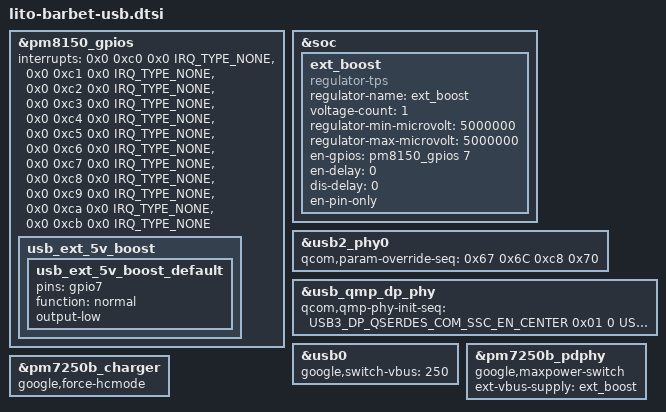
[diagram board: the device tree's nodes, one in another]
// SPDX-License-Identifier: GPL-2.0
/* Copyright (c) 2019, The Linux Foundation. All rights reserved.
 *
 * This program is free software; you can redistribute it and/or modify
 * it under the terms of the GNU General Public License version 2 and
 * only version 2 as published by the Free Software Foundation.
 *
 * This program is distributed in the hope that it will be useful,
 * but WITHOUT ANY WARRANTY; without even the implied warranty of
 * MERCHANTABILITY or FITNESS FOR A PARTICULAR PURPOSE.  See the
 * GNU General Public License for more details.
 */
#include <dt-bindings/phy/qcom,lito-qmp-usb3.h>
#include <dt-bindings/pinctrl/qcom,pmic-gpio.h>

&pm8150_gpios {
	/delete-property/ qcom,gpios-disallowed;
	interrupts = <0x0 0xc0 0x0 IRQ_TYPE_NONE>,
			<0x0 0xc1 0x0 IRQ_TYPE_NONE>,
			<0x0 0xc2 0x0 IRQ_TYPE_NONE>,
			<0x0 0xc3 0x0 IRQ_TYPE_NONE>,
			<0x0 0xc4 0x0 IRQ_TYPE_NONE>,
			<0x0 0xc5 0x0 IRQ_TYPE_NONE>,
			<0x0 0xc6 0x0 IRQ_TYPE_NONE>,
			<0x0 0xc7 0x0 IRQ_TYPE_NONE>,
			<0x0 0xc8 0x0 IRQ_TYPE_NONE>,
			<0x0 0xc9 0x0 IRQ_TYPE_NONE>,
			<0x0 0xca 0x0 IRQ_TYPE_NONE>,
			<0x0 0xcb 0x0 IRQ_TYPE_NONE>;
	interrupt-names = "pm8150_gpio1", "pm8150_gpio2",
			"pm8150_gpio3", "pm8150_gpio4",
			"pm8150_gpio5", "pm8150_gpio6",
			"pm8150_gpio7", "pm8150_gpio8",
			"pm8150_gpio9", "pm8150_gpio10",
			"pm8150_gpio11", "pm8150_gpio12";
	usb_ext_5v_boost{
		usb_ext_5v_boost_default:usb_ext_5v_boost_default {
			pins = "gpio7";
			function = "normal";
			output-low;
		};
	};
};

&soc {
	ext_boost: ext_boost {
		compatible = "regulator-tps";
		regulator-name = "ext_boost";
		voltage-count = <1>;
		regulator-min-microvolt = <5000000>;
		regulator-max-microvolt = <5000000>;
		en-gpios = <&pm8150_gpios 7 GPIO_ACTIVE_HIGH>;
		en-delay = <0>;
		dis-delay = <0>;
		en-pin-only;
		status = "okay";
	};
};

&usb2_phy0 {
	qcom,param-override-seq =
		<0x67 0x6C
		0xc8 0x70>;
};

&usb_qmp_dp_phy {
	qcom,qmp-phy-init-seq =
		/* <reg_offset, value, delay> */
		<USB3_DP_QSERDES_COM_SSC_EN_CENTER 0x01 0
		USB3_DP_QSERDES_COM_SSC_PER1 0x31 0
		USB3_DP_QSERDES_COM_SSC_PER2 0x01 0
		USB3_DP_QSERDES_COM_SSC_STEP_SIZE1_MODE0 0xDE 0
		USB3_DP_QSERDES_COM_SSC_STEP_SIZE2_MODE0 0x07 0
		USB3_DP_QSERDES_COM_SSC_STEP_SIZE1_MODE1 0xDE 0
		USB3_DP_QSERDES_COM_SSC_STEP_SIZE2_MODE1 0x07 0
		USB3_DP_QSERDES_COM_SYSCLK_BUF_ENABLE 0x0A 0
		USB3_DP_QSERDES_COM_CMN_IPTRIM 0x20 0
		USB3_DP_QSERDES_COM_CP_CTRL_MODE0 0x06 0
		USB3_DP_QSERDES_COM_CP_CTRL_MODE1 0x06 0
		USB3_DP_QSERDES_COM_PLL_RCTRL_MODE0 0x16 0
		USB3_DP_QSERDES_COM_PLL_RCTRL_MODE1 0x16 0
		USB3_DP_QSERDES_COM_PLL_CCTRL_MODE0 0x36 0
		USB3_DP_QSERDES_COM_PLL_CCTRL_MODE1 0x36 0
		USB3_DP_QSERDES_COM_SYSCLK_EN_SEL 0x1A 0
		USB3_DP_QSERDES_COM_LOCK_CMP_EN 0x04 0
		USB3_DP_QSERDES_COM_LOCK_CMP1_MODE0 0x14 0
		USB3_DP_QSERDES_COM_LOCK_CMP2_MODE0 0x34 0
		USB3_DP_QSERDES_COM_LOCK_CMP1_MODE1 0x34 0
		USB3_DP_QSERDES_COM_LOCK_CMP2_MODE1 0x82 0
		USB3_DP_QSERDES_COM_DEC_START_MODE0 0x82 0
		USB3_DP_QSERDES_COM_DEC_START_MODE1 0x82 0
		USB3_DP_QSERDES_COM_DIV_FRAC_START1_MODE0 0xAB 0
		USB3_DP_QSERDES_COM_DIV_FRAC_START2_MODE0 0xEA 0
		USB3_DP_QSERDES_COM_DIV_FRAC_START3_MODE0 0x02 0
		USB3_DP_QSERDES_COM_DIV_FRAC_START1_MODE1 0xAB 0
		USB3_DP_QSERDES_COM_DIV_FRAC_START2_MODE1 0xEA 0
		USB3_DP_QSERDES_COM_DIV_FRAC_START3_MODE1 0x02 0
		USB3_DP_QSERDES_COM_VCO_TUNE_MAP 0x02 0
		USB3_DP_QSERDES_COM_VCO_TUNE1_MODE0 0x24 0
		USB3_DP_QSERDES_COM_VCO_TUNE1_MODE1 0x24 0
		USB3_DP_QSERDES_COM_VCO_TUNE2_MODE1 0x02 0
		USB3_DP_QSERDES_COM_HSCLK_SEL 0x01 0
		USB3_DP_QSERDES_COM_CORECLK_DIV_MODE1 0x08 0
		USB3_DP_QSERDES_COM_BIN_VCOCAL_CMP_CODE1_MODE0 0xCA 0
		USB3_DP_QSERDES_COM_BIN_VCOCAL_CMP_CODE2_MODE0 0x1E 0
		USB3_DP_QSERDES_COM_BIN_VCOCAL_CMP_CODE1_MODE1 0xCA 0
		USB3_DP_QSERDES_COM_BIN_VCOCAL_CMP_CODE2_MODE1 0x1E 0
		USB3_DP_QSERDES_COM_BIN_VCOCAL_HSCLK_SEL 0x11 0
		USB3_DP_QSERDES_TXA_RES_CODE_LANE_TX 0x00 0
		USB3_DP_QSERDES_TXA_RES_CODE_LANE_RX 0x00 0
		USB3_DP_QSERDES_TXA_RES_CODE_LANE_OFFSET_TX 0x16 0
		USB3_DP_QSERDES_TXA_RES_CODE_LANE_OFFSET_RX 0x05 0
		USB3_DP_QSERDES_TXA_LANE_MODE_1 0x55 0
		USB3_DP_QSERDES_TXA_LANE_MODE_2 0x02 0
		USB3_DP_QSERDES_TXA_LANE_MODE_4 0x2A 0
		USB3_DP_QSERDES_TXA_LANE_MODE_5 0x3F 0
		USB3_DP_QSERDES_TXA_RCV_DETECT_LVL_2 0x12 0
		USB3_DP_QSERDES_TXA_PI_QEC_CTRL 0x20 0
		USB3_DP_QSERDES_RXA_UCDR_SO_GAIN 0x05 0
		USB3_DP_QSERDES_RXA_UCDR_FASTLOCK_FO_GAIN 0x2F 0
		USB3_DP_QSERDES_RXA_UCDR_SO_SATURATION_AND_ENABLE 0x7F 0
		USB3_DP_QSERDES_RXA_UCDR_FASTLOCK_COUNT_LOW 0xFF 0
		USB3_DP_QSERDES_RXA_UCDR_FASTLOCK_COUNT_HIGH 0x0F 0
		USB3_DP_QSERDES_RXA_UCDR_PI_CONTROLS 0x99 0
		USB3_DP_QSERDES_RXA_UCDR_SB2_THRESH1 0x04 0
		USB3_DP_QSERDES_RXA_UCDR_SB2_THRESH2 0x08 0
		USB3_DP_QSERDES_RXA_UCDR_SB2_GAIN1 0x05 0
		USB3_DP_QSERDES_RXA_UCDR_SB2_GAIN2 0x05 0
		USB3_DP_QSERDES_RXA_VGA_CAL_CNTRL1 0x54 0
		USB3_DP_QSERDES_RXA_VGA_CAL_CNTRL2 0x08 0
		USB3_DP_QSERDES_RXA_RX_EQU_ADAPTOR_CNTRL2 0x0F 0
		USB3_DP_QSERDES_RXA_RX_EQU_ADAPTOR_CNTRL3 0x4A 0
		USB3_DP_QSERDES_RXA_RX_EQU_ADAPTOR_CNTRL4 0x0A 0
		USB3_DP_QSERDES_RXA_RX_IDAC_TSETTLE_LOW 0xC0 0
		USB3_DP_QSERDES_RXA_RX_IDAC_TSETTLE_HIGH 0x00 0
		USB3_DP_QSERDES_RXA_RX_EQ_OFFSET_ADAPTOR_CNTRL1 0x77 0
		USB3_DP_QSERDES_RXA_SIGDET_CNTRL 0x04 0
		USB3_DP_QSERDES_RXA_SIGDET_DEGLITCH_CNTRL 0x0E 0
		USB3_DP_QSERDES_RXA_RX_MODE_00_LOW 0xBF 0
		USB3_DP_QSERDES_RXA_RX_MODE_00_HIGH 0xBF 0
		USB3_DP_QSERDES_RXA_RX_MODE_00_HIGH2 0x3F 0
		USB3_DP_QSERDES_RXA_RX_MODE_00_HIGH3 0x7F 0
		USB3_DP_QSERDES_RXA_RX_MODE_00_HIGH4 0x94 0
		USB3_DP_QSERDES_RXA_RX_MODE_01_LOW 0x5B 0
		USB3_DP_QSERDES_RXA_RX_MODE_01_HIGH 0x1B 0
		USB3_DP_QSERDES_RXA_RX_MODE_01_HIGH2 0xD2 0
		USB3_DP_QSERDES_RXA_RX_MODE_01_HIGH3 0x13 0
		USB3_DP_QSERDES_RXA_RX_MODE_01_HIGH4 0xA9 0
		USB3_DP_QSERDES_RXA_DFE_EN_TIMER 0x04 0
		USB3_DP_QSERDES_RXA_DFE_CTLE_POST_CAL_OFFSET 0x00 0
		USB3_DP_QSERDES_RXA_AUX_DATA_TCOARSE_TFINE 0xA0 0
		USB3_DP_QSERDES_RXA_DCC_CTRL1 0x0C 0
		USB3_DP_QSERDES_RXA_GM_CAL 0x00 0
		USB3_DP_QSERDES_RXA_VTH_CODE 0x10 0
		USB3_DP_QSERDES_TXB_RES_CODE_LANE_TX 0x00 0
		USB3_DP_QSERDES_TXB_RES_CODE_LANE_RX 0x00 0
		USB3_DP_QSERDES_TXB_RES_CODE_LANE_OFFSET_TX 0x16 0
		USB3_DP_QSERDES_TXB_RES_CODE_LANE_OFFSET_RX 0x05 0
		USB3_DP_QSERDES_TXB_LANE_MODE_1 0x55 0
		USB3_DP_QSERDES_TXB_LANE_MODE_2 0x02 0
		USB3_DP_QSERDES_TXB_LANE_MODE_4 0x2A 0
		USB3_DP_QSERDES_TXB_LANE_MODE_5 0x3F 0
		USB3_DP_QSERDES_TXB_RCV_DETECT_LVL_2 0x12 0
		USB3_DP_QSERDES_TXB_PI_QEC_CTRL 0x02 0
		USB3_DP_QSERDES_RXB_UCDR_SO_GAIN 0x05 0
		USB3_DP_QSERDES_RXB_UCDR_FASTLOCK_FO_GAIN 0x2F 0
		USB3_DP_QSERDES_RXB_UCDR_SO_SATURATION_AND_ENABLE 0x7F 0
		USB3_DP_QSERDES_RXB_UCDR_FASTLOCK_COUNT_LOW 0xFF 0
		USB3_DP_QSERDES_RXB_UCDR_FASTLOCK_COUNT_HIGH 0x0F 0
		USB3_DP_QSERDES_RXB_UCDR_PI_CONTROLS 0x99 0
		USB3_DP_QSERDES_RXB_UCDR_SB2_THRESH1 0x04 0
		USB3_DP_QSERDES_RXB_UCDR_SB2_THRESH2 0x08 0
		USB3_DP_QSERDES_RXB_UCDR_SB2_GAIN1 0x05 0
		USB3_DP_QSERDES_RXB_UCDR_SB2_GAIN2 0x05 0
		USB3_DP_QSERDES_RXB_VGA_CAL_CNTRL1 0x54 0
		USB3_DP_QSERDES_RXB_VGA_CAL_CNTRL2 0x08 0
		USB3_DP_QSERDES_RXB_RX_EQU_ADAPTOR_CNTRL2 0x0F 0
		USB3_DP_QSERDES_RXB_RX_EQU_ADAPTOR_CNTRL3 0x4A 0
		USB3_DP_QSERDES_RXB_RX_EQU_ADAPTOR_CNTRL4 0x0A 0
		USB3_DP_QSERDES_RXB_RX_IDAC_TSETTLE_LOW 0xC0 0
		USB3_DP_QSERDES_RXB_RX_IDAC_TSETTLE_HIGH 0x00 0
		USB3_DP_QSERDES_RXB_RX_EQ_OFFSET_ADAPTOR_CNTRL1 0x77 0
		USB3_DP_QSERDES_RXB_SIGDET_CNTRL 0x04 0
		USB3_DP_QSERDES_RXB_SIGDET_DEGLITCH_CNTRL 0x0E 0
		USB3_DP_QSERDES_RXB_RX_MODE_00_LOW 0xBF 0
		USB3_DP_QSERDES_RXB_RX_MODE_00_HIGH 0xBF 0
		USB3_DP_QSERDES_RXB_RX_MODE_00_HIGH2 0x3F 0
		USB3_DP_QSERDES_RXB_RX_MODE_00_HIGH3 0x7F 0
		USB3_DP_QSERDES_RXB_RX_MODE_00_HIGH4 0x94 0
		USB3_DP_QSERDES_RXB_RX_MODE_01_LOW 0x5B 0
		USB3_DP_QSERDES_RXB_RX_MODE_01_HIGH 0x1B 0
		USB3_DP_QSERDES_RXB_RX_MODE_01_HIGH2 0xD2 0
		USB3_DP_QSERDES_RXB_RX_MODE_01_HIGH3 0x13 0
		USB3_DP_QSERDES_RXB_RX_MODE_01_HIGH4 0xA9 0
		USB3_DP_QSERDES_RXB_DFE_EN_TIMER 0x04 0
		USB3_DP_QSERDES_RXB_DFE_CTLE_POST_CAL_OFFSET 0x00 0
		USB3_DP_QSERDES_RXB_AUX_DATA_TCOARSE_TFINE 0xA0 0
		USB3_DP_QSERDES_RXB_DCC_CTRL1 0x0C 0
		USB3_DP_QSERDES_RXB_GM_CAL 0x00 0
		USB3_DP_QSERDES_RXB_VTH_CODE 0x10 0
		USB3_DP_PCS_LOCK_DETECT_CONFIG1 0xD0 0
		USB3_DP_PCS_LOCK_DETECT_CONFIG2 0x07 0
		USB3_DP_PCS_LOCK_DETECT_CONFIG3 0x20 0
		USB3_DP_PCS_LOCK_DETECT_CONFIG6 0x13 0
		USB3_DP_PCS_REFGEN_REQ_CONFIG1 0x21 0
		USB3_DP_PCS_RX_SIGDET_LVL 0xAA 0
		USB3_DP_PCS_CDR_RESET_TIME 0x0F 0
		USB3_DP_PCS_ALIGN_DETECT_CONFIG1 0x88 0
		USB3_DP_PCS_ALIGN_DETECT_CONFIG2 0x13 0
		USB3_DP_PCS_PCS_TX_RX_CONFIG 0x0C 0
		USB3_DP_PCS_EQ_CONFIG1 0x4B 0
		USB3_DP_PCS_EQ_CONFIG5 0x10 0
		USB3_DP_PCS_USB3_LFPS_DET_HIGH_COUNT_VAL 0xF8 0
		USB3_DP_PCS_USB3_RXEQTRAINING_DFE_TIME_S2 0x07 0
		0xffffffff 0xffffffff 0x00>;
};

&usb0 {
	google,switch-vbus = <250>;
};

&pm7250b_pdphy {
	google,maxpower-switch;
	ext-vbus-supply = <&ext_boost>;
};

&pm7250b_charger {
	google,force-hcmode;
};
